# mcr_me13 register map
Registers are access not given, no defined reset value unless marked. A register's access mark holds for its fields unless they carry their own. Offsets are from the block's base; lines under a group give offsets from that group; [hi:lo] are bit positions; {n}, {i} and the like mark numbered series; 'fields as' and 'values as' point back to an identical list; <NAME> marks a mode.

## Memory map
0x40006C00 MCR size 0x400 — Misc Control.

## MCR — Misc Control.
Base 0x40006C00
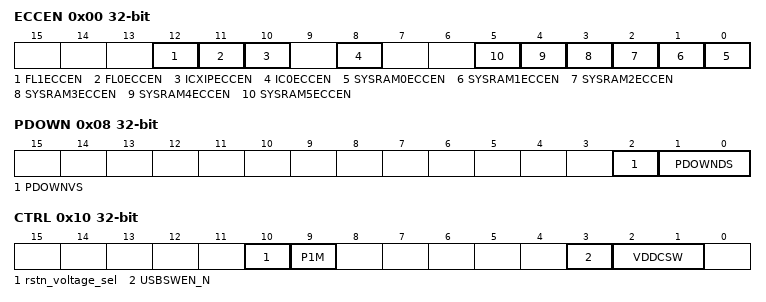
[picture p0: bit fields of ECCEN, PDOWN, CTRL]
0x00 ECCEN — ECC Enable Register
  [all] fields
    0=dis (disabled.); 1=en (enabled.)
  [12] FL1ECCEN — Flash1 ECC Enable.
  [11] FL0ECCEN — Flash0 ECC Enable.
  [10] ICXIPECCEN — IcacheXIP ECC Enable.
  [8] IC0ECCEN — Icache0 ECC Enable.
  [n] SYSRAM{n}ECCEN (n=0..5) — ECC System RAM Enable.
0x08 PDOWN — PDOWN Drive Strength
  [2] PDOWNVS — PDOWN Voltage Select
  [1:0] PDOWNDS — PDOWN Drive Strength
0x10 CTRL — Misc Power State Control Register
  [10] rstn_voltage_sel — Error! Description not Found!
  [9] P1M — Enable the Reset Pad Pull Up Resistors
    0=1m (1MOhm Pullup); 1=25k (25kOhm Pullup.)
  [3] USBSWEN_N — USB Switch Control
    1=off (USB SW off in LP modes); 0=on (USB SW On)
  [2:1] VDDCSW — Controls switching of VCORE
